AUTOSAR XML (schema 00052)
package /apd/AdaptiveApplicationSwComponentTypes
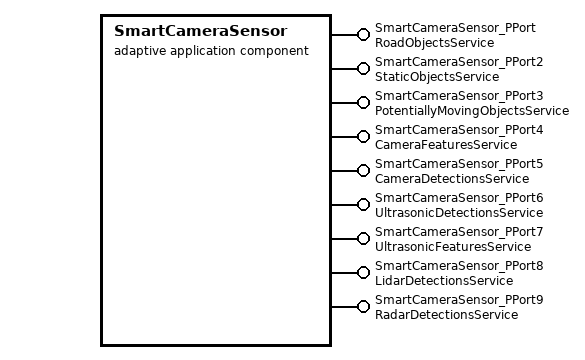
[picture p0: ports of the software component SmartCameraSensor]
  adaptive application sw component type SmartCameraSensor
    9 x provide port:
      SmartCameraSensor_PPort: provided-interface=RoadObjectsService
      SmartCameraSensor_PPort2: provided-interface=StaticObjectsService
      SmartCameraSensor_PPort3: provided-interface=PotentiallyMovingObjectsService
      SmartCameraSensor_PPort4: provided-interface=CameraFeaturesService
      SmartCameraSensor_PPort5: provided-interface=CameraDetectionsService
      SmartCameraSensor_PPort6: provided-interface=UltrasonicDetectionsService
      SmartCameraSensor_PPort7: provided-interface=UltrasonicFeaturesService
      SmartCameraSensor_PPort8: provided-interface=LidarDetectionsService
      SmartCameraSensor_PPort9: provided-interface=RadarDetectionsService
package /apd/Executables
  executable SmartCameraSensor: category=APPLICATION_LEVEL, minimum-timer-granularity=1000
    root sw component prototype SmartCameraSensor: application-type=SmartCameraSensor
